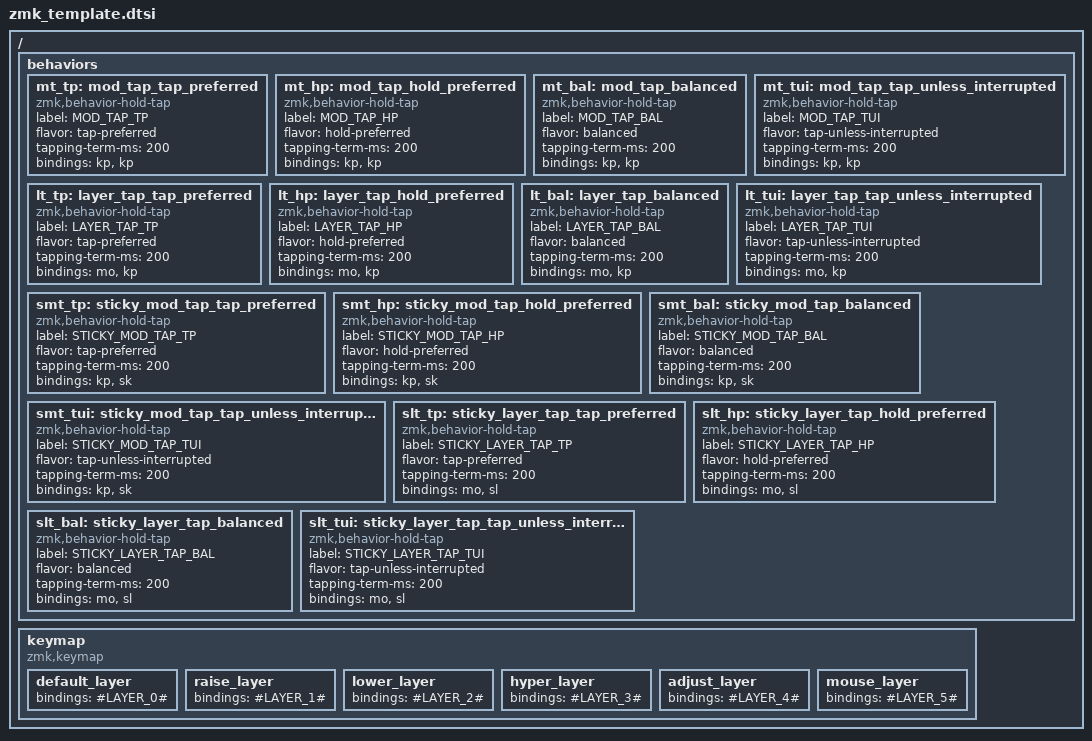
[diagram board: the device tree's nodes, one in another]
#include <behaviors.dtsi>
#include <dt-bindings/zmk/keys.h>
#include <dt-bindings/zmk/bt.h>

/ {
    // The hold-tap behaviors the keymap may use, named `<kind>_<flavor>`:
    // - mt_  holds a modifier, taps a key
    // - lt_  holds a layer, taps a key
    // - smt_ holds a modifier, sticks it on tap
    // - slt_ holds a layer, sticks it on tap
    // The flavor suffix is one of tp (tap-preferred), hp (hold-preferred),
    // bal (balanced) or tui (tap-unless-interrupted). generate_keymap.py picks
    // the behavior matching each key, defaulting to mt_tp for modifier holds
    // and lt_bal for layer holds.
    behaviors {
        mt_tp: mod_tap_tap_preferred {
            compatible = "zmk,behavior-hold-tap";
            label = "MOD_TAP_TP";
            #binding-cells = <2>;
            flavor = "tap-preferred";
            tapping-term-ms = <200>;
            bindings = <&kp>, <&kp>;
        };
        mt_hp: mod_tap_hold_preferred {
            compatible = "zmk,behavior-hold-tap";
            label = "MOD_TAP_HP";
            #binding-cells = <2>;
            flavor = "hold-preferred";
            tapping-term-ms = <200>;
            bindings = <&kp>, <&kp>;
        };
        mt_bal: mod_tap_balanced {
            compatible = "zmk,behavior-hold-tap";
            label = "MOD_TAP_BAL";
            #binding-cells = <2>;
            flavor = "balanced";
            tapping-term-ms = <200>;
            bindings = <&kp>, <&kp>;
        };
        mt_tui: mod_tap_tap_unless_interrupted {
            compatible = "zmk,behavior-hold-tap";
            label = "MOD_TAP_TUI";
            #binding-cells = <2>;
            flavor = "tap-unless-interrupted";
            tapping-term-ms = <200>;
            bindings = <&kp>, <&kp>;
        };

        lt_tp: layer_tap_tap_preferred {
            compatible = "zmk,behavior-hold-tap";
            label = "LAYER_TAP_TP";
            #binding-cells = <2>;
            flavor = "tap-preferred";
            tapping-term-ms = <200>;
            bindings = <&mo>, <&kp>;
        };
        lt_hp: layer_tap_hold_preferred {
            compatible = "zmk,behavior-hold-tap";
            label = "LAYER_TAP_HP";
            #binding-cells = <2>;
            flavor = "hold-preferred";
            tapping-term-ms = <200>;
            bindings = <&mo>, <&kp>;
        };
        lt_bal: layer_tap_balanced {
            compatible = "zmk,behavior-hold-tap";
            label = "LAYER_TAP_BAL";
            #binding-cells = <2>;
            flavor = "balanced";
            tapping-term-ms = <200>;
            bindings = <&mo>, <&kp>;
        };
        lt_tui: layer_tap_tap_unless_interrupted {
            compatible = "zmk,behavior-hold-tap";
            label = "LAYER_TAP_TUI";
            #binding-cells = <2>;
            flavor = "tap-unless-interrupted";
            tapping-term-ms = <200>;
            bindings = <&mo>, <&kp>;
        };

        smt_tp: sticky_mod_tap_tap_preferred {
            compatible = "zmk,behavior-hold-tap";
            label = "STICKY_MOD_TAP_TP";
            #binding-cells = <2>;
            flavor = "tap-preferred";
            tapping-term-ms = <200>;
            bindings = <&kp>, <&sk>;
        };
        smt_hp: sticky_mod_tap_hold_preferred {
            compatible = "zmk,behavior-hold-tap";
            label = "STICKY_MOD_TAP_HP";
            #binding-cells = <2>;
            flavor = "hold-preferred";
            tapping-term-ms = <200>;
            bindings = <&kp>, <&sk>;
        };
        smt_bal: sticky_mod_tap_balanced {
            compatible = "zmk,behavior-hold-tap";
            label = "STICKY_MOD_TAP_BAL";
            #binding-cells = <2>;
            flavor = "balanced";
            tapping-term-ms = <200>;
            bindings = <&kp>, <&sk>;
        };
        smt_tui: sticky_mod_tap_tap_unless_interrupted {
            compatible = "zmk,behavior-hold-tap";
            label = "STICKY_MOD_TAP_TUI";
            #binding-cells = <2>;
            flavor = "tap-unless-interrupted";
            tapping-term-ms = <200>;
            bindings = <&kp>, <&sk>;
        };

        slt_tp: sticky_layer_tap_tap_preferred {
            compatible = "zmk,behavior-hold-tap";
            label = "STICKY_LAYER_TAP_TP";
            #binding-cells = <2>;
            flavor = "tap-preferred";
            tapping-term-ms = <200>;
            bindings = <&mo>, <&sl>;
        };
        slt_hp: sticky_layer_tap_hold_preferred {
            compatible = "zmk,behavior-hold-tap";
            label = "STICKY_LAYER_TAP_HP";
            #binding-cells = <2>;
            flavor = "hold-preferred";
            tapping-term-ms = <200>;
            bindings = <&mo>, <&sl>;
        };
        slt_bal: sticky_layer_tap_balanced {
            compatible = "zmk,behavior-hold-tap";
            label = "STICKY_LAYER_TAP_BAL";
            #binding-cells = <2>;
            flavor = "balanced";
            tapping-term-ms = <200>;
            bindings = <&mo>, <&sl>;
        };
        slt_tui: sticky_layer_tap_tap_unless_interrupted {
            compatible = "zmk,behavior-hold-tap";
            label = "STICKY_LAYER_TAP_TUI";
            #binding-cells = <2>;
            flavor = "tap-unless-interrupted";
            tapping-term-ms = <200>;
            bindings = <&mo>, <&sl>;
        };
    };

    keymap {
            compatible = "zmk,keymap";

            default_layer {
                    bindings = <
#LAYER_0#
                    >;
            };

            raise_layer {
                    bindings = <
#LAYER_1#
                    >;
            };

            lower_layer {
                    bindings = <
#LAYER_2#
                    >;
            };

            hyper_layer {
                    bindings = <
#LAYER_3#
                    >;
            };

            adjust_layer {
                    bindings = <
#LAYER_4#
                    >;
            };

            mouse_layer {
                    bindings = <
#LAYER_5#
                    >;
            };
        };
};
